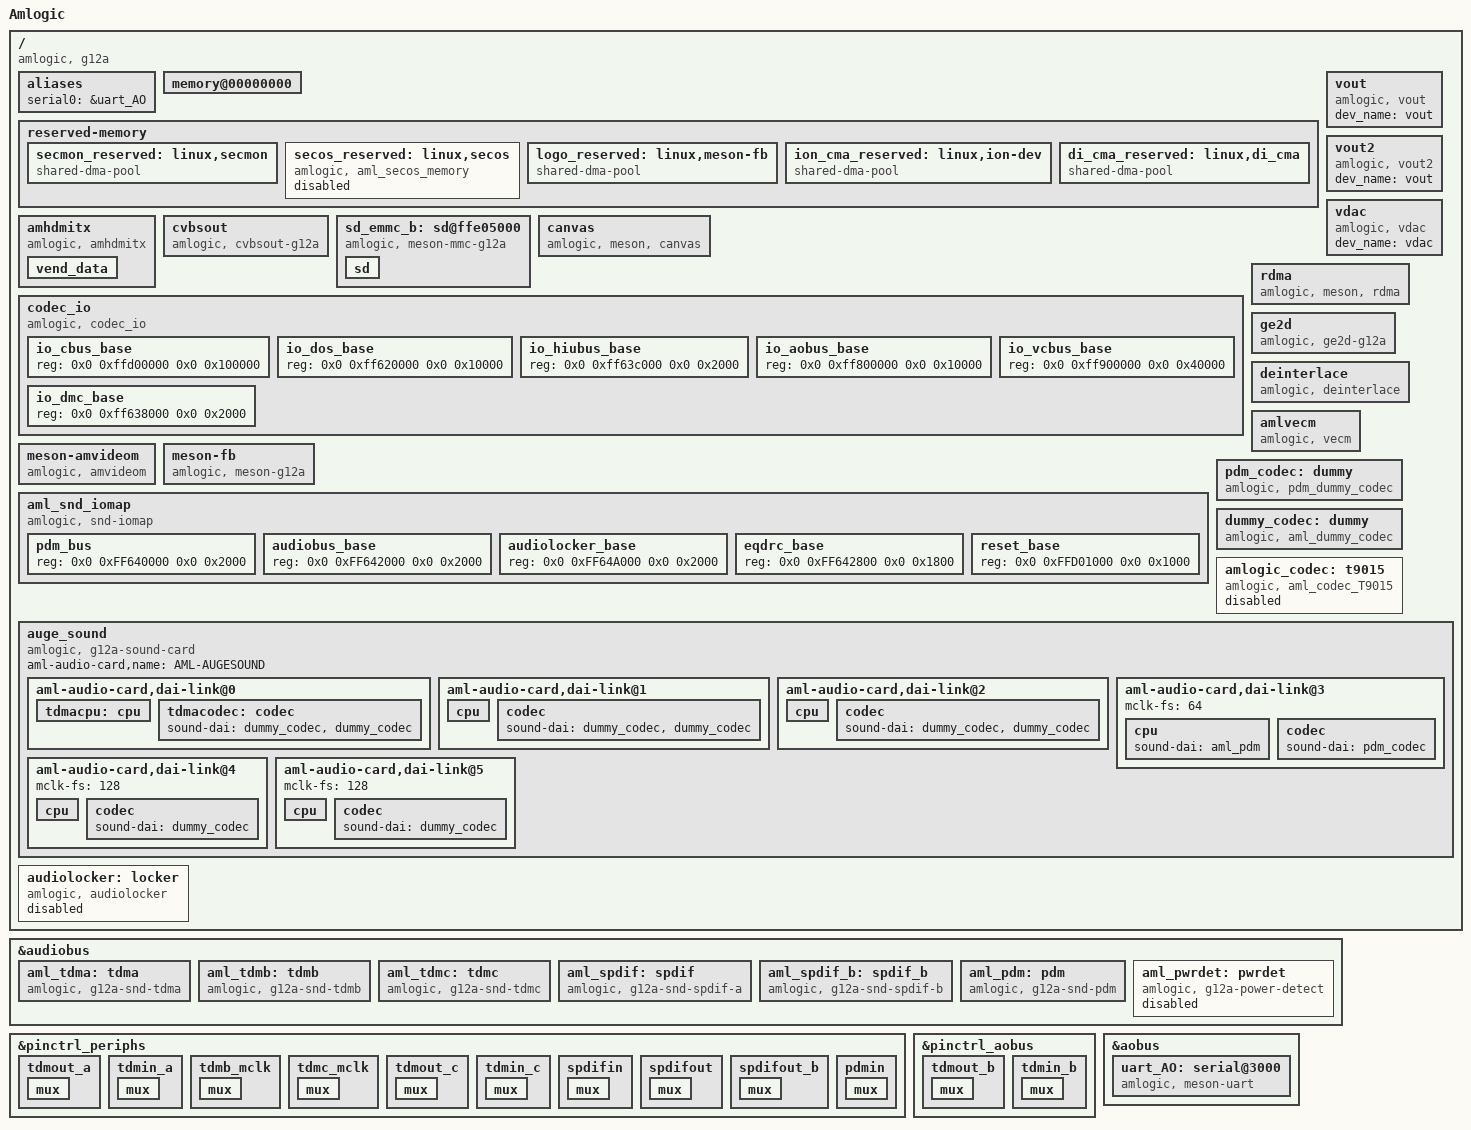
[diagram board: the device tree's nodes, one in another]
/*
 * arch/arm64/boot/dts/amlogic/g12a_pxp.dts
 *
 * Copyright (C) 2017 Amlogic, Inc. All rights reserved.
 *
 * This program is free software; you can redistribute it and/or modify
 * it under the terms of the GNU General Public License as published by
 * the Free Software Foundation; either version 2 of the License, or
 * (at your option) any later version.
 *
 * This program is distributed in the hope that it will be useful, but WITHOUT
 * ANY WARRANTY; without even the implied warranty of MERCHANTABILITY or
 * FITNESS FOR A PARTICULAR PURPOSE.  See the GNU General Public License for
 * more details.
 *
 */

/dts-v1/;

#include "mesong12a.dtsi"

/ {
	model = "Amlogic";
	compatible = "amlogic, g12a";
	interrupt-parent = <&gic>;
	#address-cells = <2>;
	#size-cells = <2>;

	aliases {
		serial0 = &uart_AO;
	};

	memory@00000000 {
		device_type = "memory";
		linux,usable-memory = <0x0 0x100000 0x0 0x3ff00000>;
	};

	reserved-memory {
		#address-cells = <2>;
		#size-cells = <2>;
		ranges;
		/* global autoconfigured region for contiguous allocations */
		secmon_reserved:linux,secmon {
			compatible = "shared-dma-pool";
			reusable;
			size = <0x0 0x400000>;
			alignment = <0x0 0x400000>;
			alloc-ranges = <0x0 0x05000000 0x0 0x400000>;
		};

		secos_reserved:linux,secos {
			status = "disable";
			compatible = "amlogic, aml_secos_memory";
			reg = <0x0 0x05300000 0x0 0x2000000>;
			no-map;
		};
		logo_reserved:linux,meson-fb {
			compatible = "shared-dma-pool";
			reusable;
			size = <0x0 0x800000>;
			alignment = <0x0 0x400000>;
			alloc-ranges = <0x0 0x3f800000 0x0 0x800000>;
		};
		ion_cma_reserved:linux,ion-dev {
			compatible = "shared-dma-pool";
			reusable;
			size = <0x0 0x8000000>;
			alignment = <0x0 0x400000>;
		};

		//di_reserved:linux,di {
			//compatible = "amlogic, di-mem";
			/* buffer_size = 3621952(yuv422 8bit) */
			/* 4179008(yuv422 10bit full pack mode) */
			/** 10x3621952=34.6M(0x23) support 8bit **/
			/** 10x4736064=45.2M(0x2e) support 12bit **/
			/** 10x4179008=40M(0x28) support 10bit **/
			//size = <0x0 0x2800000>;
			//no-map;
		//};
		/*di CMA pool */
		di_cma_reserved:linux,di_cma {
			compatible = "shared-dma-pool";
			reusable;
			/* buffer_size = 3621952(yuv422 8bit)
			 *  | 4736064(yuv422 10bit)
			 *  | 4074560(yuv422 10bit full pack mode)
			 * 10x3621952=34.6M(0x23) support 8bit
			 * 10x4736064=45.2M(0x2e) support 12bit
			 * 10x4074560=40M(0x28) support 10bit
			 */
			size = <0x0 0x02900000>;
			alignment = <0x0 0x400000>;
		};

	};

	vout {
		compatible = "amlogic, vout";
		dev_name = "vout";
		status = "okay";
	};

	vout2 {
		compatible = "amlogic, vout2";
		dev_name = "vout";
		status = "okay";
	};

	amhdmitx: amhdmitx{
		compatible = "amlogic, amhdmitx";
		dev_name = "amhdmitx";
		status = "okay";
		vend-data = <&vend_data>;
		pinctrl-names="default", "hdmitx_i2c";
		pinctrl-0=<&hdmitx_hpd &hdmitx_ddc>;
		pinctrl-1=<&hdmitx_hpd_gpio &c_i2c_master>;
		clocks = <&clkc CLKID_VAPB_MUX>,
			 <&clkc CLKID_VPU_MUX>;
		clock-names = "hdmi_vapb_clk",
			      "hdmi_vpu_clk";
		/* HPD, 57 + 32 = 89; CEC, 151 + 32 = 183*/
		interrupts = <0 57 1>;
		interrupt-names = "hdmitx_hpd";
		/* 0:M8B 1:GXBB 2:GXTVBB 3:GXL 4:GXM
		 * 5:TXL 6:TXLX 7:AXG 8:GXLX 9:TXHD
		 * 10:G12A
		 */
		ic_type = <10>;
		vend_data: vend_data{ /* Should modified by Customer */
			vendor_name = "Amlogic"; /* Max Chars: 8 */
			/* standards.ieee.org/develop/regauth/oui/oui.txt */
			vendor_id = <0x000000>;
		};
	};

	vdac {
		compatible = "amlogic, vdac";
		dev_name = "vdac";
		status = "okay";
	};

	cvbsout {
		compatible = "amlogic, cvbsout-g12a";
		dev_name = "cvbsout";
		status = "okay";
		clocks = <&clkc CLKID_VCLK2_ENCI
			&clkc CLKID_VCLK2_VENCI0
			&clkc CLKID_VCLK2_VENCI1
			&clkc CLKID_DAC_CLK>;
		clock-names = "venci_top_gate",
			"venci_0_gate",
			"venci_1_gate",
			"vdac_clk_gate";

		/* performance: reg_address, reg_value */
		/* s905x */
		performance = <0x1bf0  0x9
			0x1b56  0x343
			0x1b12  0x8080
			0x1b05  0xfd
			0x1c59  0xf752
			0xffff  0x0>; /* ending flag */
	};

	sd_emmc_b:sd@ffe05000 {
		status = "okay";
		compatible = "amlogic, meson-mmc-g12a";
		reg = <0x0 0xffe05000 0x0 0x2000>;
		interrupts = <0 190 1>;

		pinctrl-names = "sd_clk_cmd_pins", "sd_all_pins";
		pinctrl-0 = <&sd_clk_cmd_pins>;
		pinctrl-1 = <&sd_all_pins>;

		clocks = <&clkc CLKID_SD_EMMC_B>,
			<&clkc CLKID_SD_EMMC_B_P0_COMP>,
			<&clkc CLKID_FCLK_DIV2>,
			<&clkc CLKID_FCLK_DIV5>;
		clock-names = "core", "clkin0", "clkin1", "clkin2";

		bus-width = <4>;
		cap-sd-highspeed;
		cap-mmc-highspeed;
		max-frequency = <100000000>;
		non-removable;
		disable-wp;
		sd {
			pinname = "sd";
			ocr_avail = <0x200080>; /**VDD voltage 3.3 ~ 3.4 */
			caps = "MMC_CAP_4_BIT_DATA",
				 "MMC_CAP_MMC_HIGHSPEED",
				 "MMC_CAP_SD_HIGHSPEED",
				 "MMC_CAP_NONREMOVABLE",
				 "MMC_CAP_UHS_SDR12",
				 "MMC_CAP_UHS_SDR25",
				 "MMC_CAP_UHS_SDR50",
				 "MMC_PM_KEEP_POWER",
				 "MMC_CAP_NONREMOVABLE"; /**ptm debug */
			f_min = <400000>;
			f_max = <200000000>;
			max_req_size = <0x20000>; /**128KB*/
			card_type = <5>;
			/* 3:sdio device(ie:sdio-wifi),
			 * 4:SD combo (IO+mem) card
			 */
		};
	};

	canvas{
		compatible = "amlogic, meson, canvas";
		dev_name = "amlogic-canvas";
		status = "okay";
		reg = <0x0 0xff638000 0x0 0x2000>;
	};

	codec_io {
		compatible = "amlogic, codec_io";
		status = "okay";
		#address-cells=<2>;
		#size-cells=<2>;
		ranges;
		io_cbus_base{
			reg = <0x0 0xffd00000 0x0 0x100000>;
		};
		io_dos_base{
			reg = <0x0 0xff620000 0x0 0x10000>;
		};
		io_hiubus_base{
			reg = <0x0 0xff63c000 0x0 0x2000>;
		};
		io_aobus_base{
			reg = <0x0 0xff800000 0x0 0x10000>;
		};
		io_vcbus_base{
			reg = <0x0 0xff900000 0x0 0x40000>;
		};
		io_dmc_base{
			reg = <0x0 0xff638000 0x0 0x2000>;
		};
	};

	rdma{
		compatible = "amlogic, meson, rdma";
		dev_name = "amlogic-rdma";
		status = "okay";
		interrupts = <0 89 1>;
		interrupt-names = "rdma";
	};

	ge2d {
		compatible = "amlogic, ge2d-g12a";
		dev_name = "ge2d";
		status = "okay";
		interrupts = <0 146 1>;
		interrupt-names = "ge2d";
		clocks = <&clkc CLKID_VAPB_MUX>,
			<&clkc CLKID_G2D>,
			<&clkc CLKID_GE2D_GATE>;
		clock-names = "clk_vapb_0",
			"clk_ge2d",
			"clk_ge2d_gate";
		reg = <0x0 0xff940000 0x0 0x10000>;
	};

	deinterlace {
		compatible = "amlogic, deinterlace";
		status = "okay";
		/* 0:use reserved; 1:use cma; 2:use cma as reserved */
		flag_cma = <1>;
		//memory-region = <&di_reserved>;
		memory-region = <&di_cma_reserved>;
		interrupts = <0 46 1
				0 40 1>;
		interrupt-names = "pre_irq", "post_irq";
		clocks = <&clkc CLKID_VPU_MUX>,
			<&clkc CLKID_FCLK_DIV4>,
			<&clkc CLKID_VPU_CLKB_TMP_COMP>,
			<&clkc CLKID_VPU_CLKB_COMP>;
		clock-names = "vpu_mux",
			"fclk_div4",
			"vpu_clkb_tmp_composite",
			"vpu_clkb_composite";
		clock-range = <333 666>;
		/* buffer-size = <3621952>;(yuv422 8bit) */
		buffer-size = <4074560>;/*yuv422 fullpack*/
		/* reserve-iomap = "true"; */
		/* if enable nr10bit, set nr10bit-support to 1 */
		post-wr-support = <1>;
		nr10bit-support = <1>;
		nrds-enable = <1>;
		pps-enable = <1>;
	};

	amlvecm {
		compatible = "amlogic, vecm";
		dev_name = "aml_vecm";
		status = "okay";
		gamma_en = <0>;/*1:enabel ;0:disable*/
		wb_en = <0>;/*1:enabel ;0:disable*/
		cm_en = <0>;/*1:enabel ;0:disable*/
	};

	meson-amvideom {
		compatible = "amlogic, amvideom";
		dev_name = "amvideom";
		status = "okay";
		interrupts = <0 3 1>;
		interrupt-names = "vsync";
	};

	meson-fb {
		compatible = "amlogic, meson-g12a";
		memory-region = <&logo_reserved>;
		dev_name = "meson-fb";
		status = "okay";
		interrupts = <0 3 1
			0 89 1>;
		interrupt-names = "viu-vsync", "rdma";
		mem_size = <0x00800000 0x1980000 0x100000 0x100000>;
		/* uboot logo,fb0/fb1 memory size,if afbcd fb0=0x01851000*/
		display_mode_default = "1080p60hz";
		scale_mode = <1>;
		/** 0:VPU free scale 1:OSD free scale 2:OSD super scale */
		display_size_default = <1920 1080 1920 2160 32>;
		/*1920*1080*4*3 = 0x17BB000*/
		pxp_mode = <1>; /** 0:normal mode 1:pxp mode */
		mem_alloc = <1>;
		logo_addr = "0x3f800000";
	};

	/* Audio Related start */
	/* Sound iomap */
	aml_snd_iomap {
		compatible = "amlogic, snd-iomap";
		status = "okay";
		#address-cells=<2>;
		#size-cells=<2>;
		ranges;
		pdm_bus {
			reg = <0x0 0xFF640000 0x0 0x2000>;
		};
		audiobus_base {
			reg = <0x0 0xFF642000 0x0 0x2000>;
		};
		audiolocker_base {
			reg = <0x0 0xFF64A000 0x0 0x2000>;
		};
		eqdrc_base {
			reg = <0x0 0xFF642800 0x0 0x1800>;
		};
		reset_base {
			reg = <0x0 0xFFD01000 0x0 0x1000>;
		};
	};
	pdm_codec:dummy{
		#sound-dai-cells = <0>;
		compatible = "amlogic, pdm_dummy_codec";
		status = "okay";
	};
	dummy_codec:dummy{
		#sound-dai-cells = <0>;
		compatible = "amlogic, aml_dummy_codec";
		status = "okay";
	};
	amlogic_codec:t9015{
		#sound-dai-cells = <0>;
		compatible = "amlogic, aml_codec_T9015";
		reg = <0x0 0xFF632000 0x0 0x2000>;
		is_auge_used = <1>; /* meson or auge chipset used */
		tdmout_index = <0>;
		status = "disabled";
	};
	auge_sound {
		compatible = "amlogic, g12a-sound-card";
		aml-audio-card,name = "AML-AUGESOUND";

		aml-audio-card,dai-link@0 {
			format = "dsp_a";
			mclk-fs = <512>;
			//continuous-clock;
			//bitclock-inversion;
			//frame-inversion;
			//bitclock-master = <&tdmacodec>;
			//frame-master = <&tdmacodec>;
			tdmacpu: cpu {
				sound-dai = <&aml_tdma>;
				dai-tdm-slot-tx-mask =
							<1 1 1 1 1 1 1 1>;
				dai-tdm-slot-rx-mask =
							<1 1 1 1 1 1 1 1>;
				dai-tdm-slot-num = <8>;
				dai-tdm-slot-width = <32>;
				system-clock-frequency = <24576000>;
			};
			tdmacodec: codec {
				sound-dai = <&dummy_codec &dummy_codec>;
			};
		};

		aml-audio-card,dai-link@1 {
			format = "i2s";
			mclk-fs = <256>;
			//continuous-clock;
			//bitclock-inversion;
			//frame-inversion;
			bitclock-master = <&aml_tdmb>;
			frame-master = <&aml_tdmb>;
			cpu {
				sound-dai = <&aml_tdmb>;
				dai-tdm-slot-tx-mask = <1 1>;
				dai-tdm-slot-rx-mask = <1 1>;
				dai-tdm-slot-num = <2>;
				dai-tdm-slot-width = <32>;
				system-clock-frequency = <12288000>;
			};
			codec {
				sound-dai = <&dummy_codec &dummy_codec>;
			};
		};

		aml-audio-card,dai-link@2 {
			format = "i2s";
			mclk-fs = <256>;
			continuous-clock;
			//bitclock-inversion;
			//frame-inversion;
			bitclock-master = <&aml_tdmc>;
			frame-master = <&aml_tdmc>;
			cpu {
				sound-dai = <&aml_tdmc>;
				dai-tdm-slot-tx-mask = <1 1>;
				dai-tdm-slot-rx-mask = <1 1>;
				dai-tdm-slot-num = <2>;
				dai-tdm-slot-width = <32>;
				system-clock-frequency = <12288000>;
			};
			codec {
				sound-dai = <&dummy_codec &dummy_codec>;
			};
		};

		aml-audio-card,dai-link@3 {
			mclk-fs = <64>;
			cpu {
				sound-dai = <&aml_pdm>;
			};
			codec {
				sound-dai = <&pdm_codec>;
			};
		};

		aml-audio-card,dai-link@4 {
			mclk-fs = <128>;
			cpu {
				sound-dai = <&aml_spdif>;
				system-clock-frequency = <6144000>;
			};
			codec {
				sound-dai = <&dummy_codec>;
			};
		};
		aml-audio-card,dai-link@5 {
			mclk-fs = <128>;
			cpu {
				sound-dai = <&aml_spdif_b>;
				system-clock-frequency = <6144000>;
			};
			codec {
				sound-dai = <&dummy_codec>;
			};
		};
	};
	audiolocker: locker {
		compatible = "amlogic, audiolocker";
		clocks = <&clkaudio CLKID_AUDIO_LOCKER_OUT
				&clkaudio CLKID_AUDIO_LOCKER_IN
				&clkaudio CLKID_AUDIO_MCLK_D
				&clkaudio CLKID_AUDIO_MCLK_E
				&clkc CLKID_MPLL1
				&clkc CLKID_MPLL2>;
		clock-names = "lock_out", "lock_in", "out_src",
					"in_src", "out_calc", "in_ref";
		interrupts = <GIC_SPI 1 IRQ_TYPE_EDGE_RISING>;
		interrupt-names = "irq";
		frequency = <49000000>; /* pll */
		dividor = <49>; /* locker's parent */
		status = "disabled";
	};
	/* Audio Related end */
}; /* end of / */

&audiobus {
	aml_tdma: tdma {
		compatible = "amlogic, g12a-snd-tdma";
		#sound-dai-cells = <0>;
		dai-tdm-lane-slot-mask-in = <1 0>;
		dai-tdm-lane-slot-mask-out = <0 1>;
		dai-tdm-clk-sel = <0>;
		clocks = <&clkaudio CLKID_AUDIO_MCLK_A
				&clkc CLKID_MPLL0>;
		clock-names = "mclk", "clk_srcpll";
		pinctrl-names = "tdm_pins";
		pinctrl-0 = <&tdmout_a &tdmin_a>;
	};

	aml_tdmb: tdmb {
		compatible = "amlogic, g12a-snd-tdmb";
		#sound-dai-cells = <0>;
		dai-tdm-lane-slot-mask-in = <1 1 1 1>;
		dai-tdm-clk-sel = <1>;
		clocks = <&clkaudio CLKID_AUDIO_MCLK_B
				&clkc CLKID_MPLL1>;
		clock-names = "mclk", "clk_srcpll";
		pinctrl-names = "tdm_pins";
		pinctrl-0 = <&tdmb_mclk /*&tdmout_b &tdmin_b*/>;
	};

	aml_tdmc: tdmc {
		compatible = "amlogic, g12a-snd-tdmc";
		#sound-dai-cells = <0>;
		dai-tdm-lane-slot-mask-in = <0 1 0 0>;
		#dai-tdm-lane-slot-mask-out = <1 0 1 1>;
		#dai-tdm-lane-oe-slot-mask-in = <0 0 0 0>;
		dai-tdm-lane-oe-slot-mask-out = <1 0 0 0>;
		dai-tdm-clk-sel = <2>;
		clocks = <&clkaudio CLKID_AUDIO_MCLK_C
				&clkc CLKID_MPLL2>;
		clock-names = "mclk", "clk_srcpll";
		pinctrl-names = "tdm_pins";
		pinctrl-0 = <&tdmc_mclk &tdmout_c &tdmin_c>;
	};

	aml_spdif: spdif {
		compatible = "amlogic, g12a-snd-spdif-a";
		#sound-dai-cells = <0>;
		clocks = <&clkc CLKID_MPLL0
				&clkc CLKID_FCLK_DIV4
				&clkaudio CLKID_AUDIO_SPDIFIN
				&clkaudio CLKID_AUDIO_SPDIFOUT
				&clkaudio CLKID_AUDIO_SPDIFIN_CTRL
				&clkaudio CLKID_AUDIO_SPDIFOUT_CTRL>;
		clock-names = "sysclk", "fixed_clk", "gate_spdifin",
				"gate_spdifout", "clk_spdifin", "clk_spdifout";
		interrupts =
				<GIC_SPI 87 IRQ_TYPE_EDGE_RISING>;

		interrupt-names = "irq_spdifin";
		pinctrl-names = "spdif_pins";
		pinctrl-0 = <&spdifout &spdifin>;
		status = "okay";
	};
	aml_spdif_b: spdif_b {
		compatible = "amlogic, g12a-snd-spdif-b";
		#sound-dai-cells = <0>;
		clocks = <&clkc CLKID_MPLL0 /*CLKID_HIFI_PLL*/
				&clkaudio CLKID_AUDIO_SPDIFOUTB
				&clkaudio CLKID_AUDIO_SPDIFOUTB_CTRL>;
		clock-names = "sysclk",
				"gate_spdifout", "clk_spdifout";
		pinctrl-names = "spdif_pins";
		pinctrl-0 = <&spdifout_b>;
		status = "okay";
	};
	aml_pdm: pdm {
		compatible = "amlogic, g12a-snd-pdm";
		#sound-dai-cells = <0>;
		clocks = <&clkaudio CLKID_AUDIO_PDM
			&clkc CLKID_FCLK_DIV3
			&clkc CLKID_MPLL3
			&clkaudio CLKID_AUDIO_PDMIN0
			&clkaudio CLKID_AUDIO_PDMIN1>;
		clock-names = "gate",
			"sysclk_srcpll",
			"dclk_srcpll",
			"pdm_dclk",
			"pdm_sysclk";
		pinctrl-names = "pdm_pins";
		pinctrl-0 = <&pdmin>;
		filter_mode = <1>; /* mode 0~4, defalut:1 */
		status = "okay";
	};
	aml_pwrdet: pwrdet {
		compatible = "amlogic, g12a-power-detect";

		interrupts = <GIC_SPI 155 IRQ_TYPE_EDGE_RISING>;
		interrupt-names = "pwrdet_irq";

		/* pwrdet source sel
		 * 7: loopback;
		 * 6: tdmin_lb;
		 * 5: reserved;
		 * 4: pdmin;
		 * 3: spdifin;
		 * 2: tdmin_c;
		 * 1: tdmin_b;
		 * 0: tdmin_a;
		 */
		pwrdet_src = <4>;

		hi_th = <0x70000>;
		lo_th = <0x16000>;

		status = "disabled";
	};
}; /* end of audiobus */

&pinctrl_periphs {
	tdmout_a: tdmout_a {
		mux { /* GPIOX_11, GPIOX_10, GPIOX_8 */
			groups = "tdma_sclk",
				"tdma_fs",
				"tdma_dout1";
			function = "tdma_out";
		};
	};

	tdmin_a: tdmin_a {
		mux { /* GPIOX_9 */
			groups = "tdma_din0";
			function = "tdma_in";
		};
	};

	tdmb_mclk: tdmb_mclk {
		mux {
			groups = "mclk0_a";
			function = "mclk0";
		};
	};

	tdmc_mclk: tdmc_mclk {
		mux { /* GPIOZ_8 */
			groups = "mclk1_z";
			function = "mclk1";
		};
	};

	tdmout_c:tdmout_c {
		mux { /* gpioz_7, gpioz_6, GPIOZ_2, GPIOZ_4, GPIOZ_5*/
			groups = "tdmc_sclk_z",
				"tdmc_fs_z",
				"tdmc_dout0_z"
				/*,"tdmc_dout2_z",
				 *"tdmc_dout3_z"
				 */;
			function = "tdmc_out";
		};
	};

	tdmin_c:tdmin_c {
		mux { /* GPIOZ_3 */
			groups = "tdmc_din1_z";
			function = "tdmc_in";
		};
	};

	spdifin: spdifin {
		mux {/* gpioa_10 */
			groups = "spdif_in_a10";
			function = "spdif_in";
		};
	};

	spdifout: spdifout {
		mux {/* gpioa_11 */
			groups = "spdif_out_a11";
			function = "spdif_out";
		};
	};

	spdifout_b: spdifout_b {
		mux { /* gpioa_13 */
			groups = "spdif_out_a13";
			function = "spdif_out";
		};
	};

	pdmin: pdmin {
		mux { /* gpioa_5, gpioa_6, gpioa_7, gpioa_8, gpioa_9*/
			groups = "pdm_din0_a",
			"pdm_din1_a",
			"pdm_din2_a",
			"pdm_din3_a",
			"pdm_dclk_a";
			function = "pdm";
		};
	};

}; /* end of pinctrl_periphs */

&pinctrl_aobus {
	tdmout_b: tdmout_b {
		mux { /* GPIOAO_7, GPIOAO_8, GPIOAO_4 */
			groups = "tdmb_fs_ao",
				"tdmb_fs_ao",
				"tdmb_dout0_ao";
			function = "tdmb_out_ao";
		};
	};

	tdmin_b:tdmin_b {
		mux {
			groups = "tdmb_din2_ao";
			function = "tdmb_in_ao";
		};
	};
};  /* end of pinctrl_aobus */
/* Audio Related End */

&aobus{
	uart_AO: serial@3000 {
		compatible = "amlogic, meson-uart";
		reg = <0x0 0x3000 0x0 0x18>;
		interrupts = <0 193 1>;
		status = "okay";
		clocks = <&xtal>;
		clock-names = "clk_uart";
		xtal_tick_en = <1>;
		fifosize = < 64 >;
		pinctrl-names = "default";
		pinctrl-0 = <&ao_uart_pins>;
		support-sysrq = <0>;    /* 0 not support , 1 support */
	};
};
